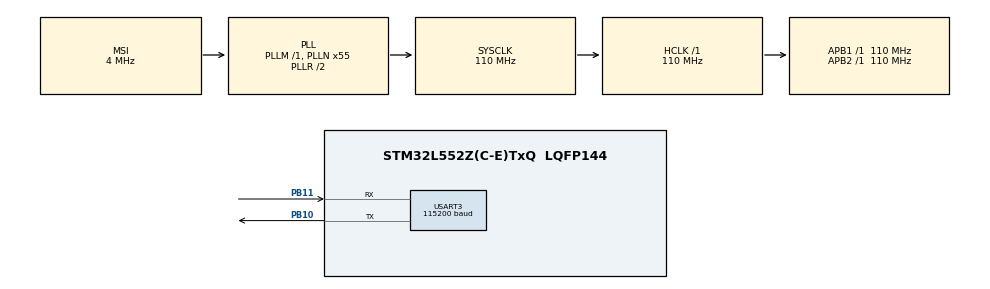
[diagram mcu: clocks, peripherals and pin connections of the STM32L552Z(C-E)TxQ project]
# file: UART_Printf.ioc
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Mcu.Family=STM32L5
Mcu.Name=STM32L552Z(C-E)TxQ
Mcu.Package=LQFP144
NVIC.PriorityGroup=NVIC_PRIORITYGROUP_3
PB10.GPIO_PuPd=GPIO_PULLUP
PB10.Mode=Asynchronous
PB10.Signal=USART3_TX
PB11.GPIO_PuPd=GPIO_PULLUP
PB11.Mode=Asynchronous
PB11.Signal=USART3_RX
ProjectManager.HeapSize=0x200
ProjectManager.StackSize=0x400
ProjectManager.TargetToolchain=EWARM V8.32
RCC.ADCCLockSelection=RCC_ADCCLKSOURCE_SYSCLK
RCC.ADCFreq_Value=110000000
RCC.AHBFreq_Value=110000000
RCC.APB1Freq_Value=110000000
RCC.APB1TimFreq_Value=110000000
RCC.APB2Freq_Value=110000000
RCC.APB2TimFreq_Value=110000000
RCC.CortexFreq_Value=110000000
RCC.DATA_CACHE_ENABLE=0
RCC.HCLKFreq_Value=110000000
RCC.HSE_VALUE=16000000
RCC.HSI48_VALUE=48000000
RCC.HSI_VALUE=16000000
RCC.INSTRUCTION_CACHE_ENABLE=0
RCC.LSE_VALUE=32768
RCC.MSI_VALUE=4000000
RCC.PLLN=55
RCC.SYSCLKFreq_VALUE=110000000
RCC.SYSCLKSource=RCC_SYSCLKSOURCE_PLLCLK
RCC.VCOOutputFreq_Value=220000000
USART3.AutoBaudRateEnableParam=UART_ADVFEATURE_AUTOBAUDRATE_DISABLE
USART3.BaudRate=115200
USART3.DMADisableonRxErrorParam=ADVFEATURE_DMA_ENABLEONRXERROR
USART3.DataInvertParam=ADVFEATURE_DATAINV_DISABLE
USART3.MSBFirstParam=ADVFEATURE_MSBFIRST_DISABLE
USART3.Mode=MODE_TX_RX
USART3.OneBitSampling=UART_ONE_BIT_SAMPLE_DISABLE
USART3.OverSampling=UART_OVERSAMPLING_16
USART3.OverrunDisableParam=ADVFEATURE_OVERRUN_ENABLE
USART3.Parity=PARITY_ODD
USART3.RxPinLevelInvertParam=ADVFEATURE_RXINV_DISABLE
USART3.StopBits=STOPBITS_1
USART3.SwapParam=ADVFEATURE_SWAP_DISABLE
USART3.TxPinLevelInvertParam=ADVFEATURE_TXINV_DISABLE
USART3.VirtualMode-Asynchronous=VM_ASYNC
USART3.WordLength=WORDLENGTH_8B
VP_ICACHE_VS_ICACHE.Mode=DirectMappedCache
VP_PWR_VS_DBSignals.Mode=DisableDeadBatterySignals
board=custom

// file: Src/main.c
/* USER CODE BEGIN Header */
/**
  ******************************************************************************
  * @file    UART/UART_Printf/Src/main.c
  * @author  MCD Application Team
  * @brief   This example shows how to retarget the C library printf function
  *          to the UART.
  ******************************************************************************
  * @attention
  *
  * Copyright (c) 2019 STMicroelectronics.
  * All rights reserved.
  *
  * This software is licensed under terms that can be found in the LICENSE file
  * in the root directory of this software component.
  * If no LICENSE file comes with this software, it is provided AS-IS.
  *
  ******************************************************************************
  */
/* USER CODE END Header */
#include "main.h"

UART_HandleTypeDef huart3;

void SystemClock_Config(void);
static void MX_GPIO_Init(void);
static void MX_ICACHE_Init(void);
static void MX_USART3_UART_Init(void);
/* USER CODE BEGIN PFP */
#if defined(__ARMCC_VERSION) || defined(__ICCARM__)
#define PUTCHAR_PROTOTYPE int fputc(int ch, FILE *f)
#elif defined(__GNUC__)
/* With GCC, small printf (option LD Linker->Libraries->Small printf
   set to 'Yes') calls __io_putchar() */
#define PUTCHAR_PROTOTYPE int __io_putchar(int ch)
#endif
/* USER CODE END PFP */

int main(void)
{
  /* USER CODE BEGIN 1 */

  /* STM32L5xx HAL library initialization:
       - Systick timer is configured by default as source of time base, but user
         can eventually implement his proper time base source (a general purpose
         timer for example or other time source), keeping in mind that Time base
         duration should be kept 1ms since PPP_TIMEOUT_VALUEs are defined and
         handled in milliseconds basis.
       - Set NVIC Group Priority to 3
       - Low Level Initialization
     */
  /* USER CODE END 1 */

  /* MCU Configuration--------------------------------------------------------*/

  /* Reset of all peripherals, Initializes the Flash interface and the Systick. */
  HAL_Init();

  /* USER CODE BEGIN Init */
  /* Initialize LED5 */
  BSP_LED_Init(LED5);
  /* USER CODE END Init */

  /* Configure the system clock */
  SystemClock_Config();

  /* Initialize all configured peripherals */
  MX_GPIO_Init();
  MX_ICACHE_Init();
  MX_USART3_UART_Init();
  /* USER CODE BEGIN 2 */

  /* Output a message on Hyperterminal using printf function */
  printf("\n\r UART Printf Example: retarget the C library printf function to the UART\n\r");
  printf("** Test finished successfully. ** \n\r");
  /* USER CODE END 2 */

  /* Infinite loop */
  while (1)
  {

  }
}

void SystemClock_Config(void)
{
  RCC_OscInitTypeDef RCC_OscInitStruct = {0};
  RCC_ClkInitTypeDef RCC_ClkInitStruct = {0};

  /** Configure the main internal regulator output voltage
  */
  if (HAL_PWREx_ControlVoltageScaling(PWR_REGULATOR_VOLTAGE_SCALE0) != HAL_OK)
  {
    Error_Handler();
  }

  /** Initializes the RCC Oscillators according to the specified parameters
  * in the RCC_OscInitTypeDef structure.
  */
  RCC_OscInitStruct.OscillatorType = RCC_OSCILLATORTYPE_MSI;
  RCC_OscInitStruct.MSIState = RCC_MSI_ON;
  RCC_OscInitStruct.MSICalibrationValue = RCC_MSICALIBRATION_DEFAULT;
  RCC_OscInitStruct.MSIClockRange = RCC_MSIRANGE_6;
  RCC_OscInitStruct.PLL.PLLState = RCC_PLL_ON;
  RCC_OscInitStruct.PLL.PLLSource = RCC_PLLSOURCE_MSI;
  RCC_OscInitStruct.PLL.PLLM = 1;
  RCC_OscInitStruct.PLL.PLLN = 55;
  RCC_OscInitStruct.PLL.PLLP = RCC_PLLP_DIV7;
  RCC_OscInitStruct.PLL.PLLQ = RCC_PLLQ_DIV2;
  RCC_OscInitStruct.PLL.PLLR = RCC_PLLR_DIV2;
  if (HAL_RCC_OscConfig(&RCC_OscInitStruct) != HAL_OK)
  {
    Error_Handler();
  }

  /** Initializes the CPU, AHB and APB buses clocks
  */
  RCC_ClkInitStruct.ClockType = RCC_CLOCKTYPE_HCLK|RCC_CLOCKTYPE_SYSCLK
                              |RCC_CLOCKTYPE_PCLK1|RCC_CLOCKTYPE_PCLK2;
  RCC_ClkInitStruct.SYSCLKSource = RCC_SYSCLKSOURCE_PLLCLK;
  RCC_ClkInitStruct.AHBCLKDivider = RCC_SYSCLK_DIV1;
  RCC_ClkInitStruct.APB1CLKDivider = RCC_HCLK_DIV1;
  RCC_ClkInitStruct.APB2CLKDivider = RCC_HCLK_DIV1;

  if (HAL_RCC_ClockConfig(&RCC_ClkInitStruct, FLASH_LATENCY_5) != HAL_OK)
  {
    Error_Handler();
  }
}

static void MX_ICACHE_Init(void)
{

  /** Enable instruction cache in 1-way (direct mapped cache)
  */
  if (HAL_ICACHE_ConfigAssociativityMode(ICACHE_1WAY) != HAL_OK)
  {
    Error_Handler();
  }
  if (HAL_ICACHE_Enable() != HAL_OK)
  {
    Error_Handler();
  }

}

static void MX_USART3_UART_Init(void)
{

  huart3.Instance = USART3;
  huart3.Init.BaudRate = 115200;
  huart3.Init.WordLength = UART_WORDLENGTH_8B;
  huart3.Init.StopBits = UART_STOPBITS_1;
  huart3.Init.Parity = UART_PARITY_ODD;
  huart3.Init.Mode = UART_MODE_TX_RX;
  huart3.Init.HwFlowCtl = UART_HWCONTROL_NONE;
  huart3.Init.OverSampling = UART_OVERSAMPLING_16;
  huart3.Init.OneBitSampling = UART_ONE_BIT_SAMPLE_DISABLE;
  huart3.Init.ClockPrescaler = UART_PRESCALER_DIV1;
  huart3.AdvancedInit.AdvFeatureInit = UART_ADVFEATURE_NO_INIT;
  if (HAL_UART_Init(&huart3) != HAL_OK)
  {
    Error_Handler();
  }
  if (HAL_UARTEx_SetTxFifoThreshold(&huart3, UART_TXFIFO_THRESHOLD_1_8) != HAL_OK)
  {
    Error_Handler();
  }
  if (HAL_UARTEx_SetRxFifoThreshold(&huart3, UART_RXFIFO_THRESHOLD_1_8) != HAL_OK)
  {
    Error_Handler();
  }
  if (HAL_UARTEx_DisableFifoMode(&huart3) != HAL_OK)
  {
    Error_Handler();
  }

}

static void MX_GPIO_Init(void)
{

  /* GPIO Ports Clock Enable */
  __HAL_RCC_GPIOB_CLK_ENABLE();

}

/* USER CODE BEGIN 4 */
/**
  * @brief  Retargets the C library printf function to the USART.
  * @param  None
  * @retval None
  */
PUTCHAR_PROTOTYPE
{
  /* Place your implementation of fputc here */
  /* e.g. write a character to the USART3 and Loop until the end of transmission */
  HAL_UART_Transmit(&huart3, (uint8_t *)&ch, 1, 0xFFFF);

  return ch;
}

/* USER CODE END 4 */

void Error_Handler(void)
{
  /* USER CODE BEGIN Error_Handler_Debug */
  /* User can add his own implementation to report the HAL error return state */
  /* Turn LED5 on */
  BSP_LED_On(LED5);
  while (1);
  /* USER CODE END Error_Handler_Debug */
}
